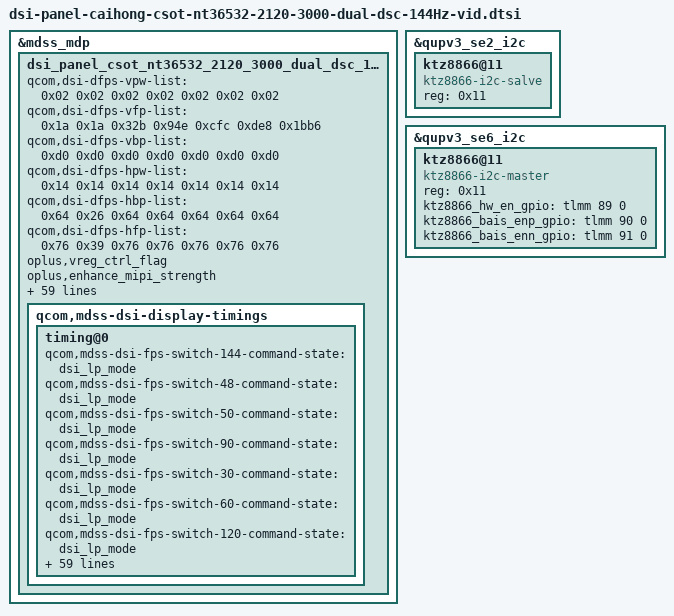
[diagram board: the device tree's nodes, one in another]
&mdss_mdp {
	dsi_panel_csot_nt36532_2120_3000_dual_dsc_144hz_vid: qcom,mdss_dsi_panel_csot_nt36532_2120_3000_dual_dsc_144hz_vid {
		qcom,dsi-dfps-vpw-list = <0x02 0x02 0x02 0x02 0x02 0x02 0x02>;
		qcom,dsi-dfps-vfp-list = <0x1a 0x1a 0x32b 0x94e 0xcfc 0xde8 0x1bb6>;
		qcom,dsi-dfps-vbp-list = <0xd0 0xd0 0xd0 0xd0 0xd0 0xd0 0xd0>;
		qcom,dsi-dfps-hpw-list = <0x14 0x14 0x14 0x14 0x14 0x14 0x14>;
		qcom,dsi-dfps-hbp-list = <0x64 0x26 0x64 0x64 0x64 0x64 0x64>;
		qcom,dsi-dfps-hfp-list = <0x76 0x39 0x76 0x76 0x76 0x76 0x76>;
		oplus,vreg_ctrl_flag;
		oplus,enhance_mipi_strength;
		oplus,dsi-cabc-enabled;
		qcom,mdss-dsi-panel-blackness-level = <0x7ff>;
		qcom,mdss-dsi-panel-average-brightness = <0x1e8480>;
		qcom,mdss-dsi-panel-peak-brightness = <0x5265c0>;
		qcom,mdss-dsi-panel-hdr-color-primaries = <0x3d13 0x4042 0x84d0 0x3e80 0x33c2 0x86c4 0x1d4c 0xbb8>;
		qcom,mdss-dsi-panel-hdr-enabled;
		qcom,mdss-pan-physical-height-dimension = <0xb1>;
		qcom,mdss-pan-physical-width-dimension = <0xfa>;
		qcom,mdss-dsi-reset-sequence = <0x01 0x0a 0x00 0x05 0x01 0x0a>;
		qcom,mdss-dsi-lp11-init;
		qcom,mdss-dsi-tx-eot-append;
		qcom,mdss-dsi-mdp-trigger = "none";
		qcom,mdss-dsi-dma-trigger = "trigger_sw";
		qcom,mdss-dsi-lane-3-state;
		qcom,mdss-dsi-lane-2-state;
		qcom,mdss-dsi-lane-1-state;
		qcom,mdss-dsi-lane-0-state;
		qcom,mdss-dsi-bllp-power-mode;
		qcom,mdss-dsi-bllp-eof-power-mode;
		qcom,bl-update-flag = "delay_until_first_frame";
		qcom,mdss-dsi-traffic-mode = "non_burst_sync_event";
		qcom,mdss-dsi-border-color = <0x00>;
		qcom,mdss-dsi-bpp = <0x18>;
		qcom,mdss-dsi-stream = <0x00>;
		qcom,mdss-dsi-virtual-channel-id = <0x00>;
		oplus,mdss-dsi-manufacture = "csot-novatek";
		oplus,mdss-dsi-vendor-name = "CSOT-NT36532";
		qcom,mdss-dsi-panel-type = "dsi_video_mode";
		qcom,mdss-dsi-panel-name = "Dual dsi csot nt36532 video mode panel with DSC";

		qcom,mdss-dsi-display-timings {
			timing@0 {
				qcom,mdss-dsi-fps-switch-144-command-state = "dsi_lp_mode";
				qcom,mdss-dsi-fps-switch-48-command-state = "dsi_lp_mode";
				qcom,mdss-dsi-fps-switch-50-command-state = "dsi_lp_mode";
				qcom,mdss-dsi-fps-switch-90-command-state = "dsi_lp_mode";
				qcom,mdss-dsi-fps-switch-30-command-state = "dsi_lp_mode";
				qcom,mdss-dsi-fps-switch-60-command-state = "dsi_lp_mode";
				qcom,mdss-dsi-fps-switch-120-command-state = "dsi_lp_mode";
				qcom,default-topology-index = <0x00>;
				qcom,display-topology = <0x04 0x04 0x02>;
				qcom,mdss-dsi-fps-switch-144-command = [39 00 00 40 00 00 02 b2 00 39 00 00 00 00 00 02 b3 00];
				qcom,mdss-dsi-fps-switch-48-command = [39 00 00 40 00 00 02 b2 00 39 00 00 00 00 00 02 b3 80];
				qcom,mdss-dsi-fps-switch-50-command = [39 00 00 40 00 00 02 b2 00 39 00 00 00 00 00 02 b3 80];
				qcom,mdss-dsi-fps-switch-90-command = [39 00 00 40 00 00 02 b2 00 39 00 00 00 00 00 02 b3 80];
				qcom,mdss-dsi-fps-switch-30-command = [39 00 00 40 00 00 02 b2 91 39 00 00 00 00 00 02 b3 40];
				qcom,mdss-dsi-fps-switch-60-command = [39 00 00 40 00 00 02 b2 91 39 00 00 00 00 00 02 b3 40];
				qcom,mdss-dsi-fps-switch-120-command = [39 00 00 40 00 00 02 b2 91 39 00 00 00 00 00 02 b3 40];
				qcom,mdss-dsc-block-prediction-enable;
				qcom,mdss-dsc-bit-per-pixel = <0x08>;
				qcom,mdss-dsc-bit-per-component = <0x08>;
				qcom,mdss-dsc-slice-per-pkt = <0x02>;
				qcom,mdss-dsc-slice-width = <0x2ee>;
				qcom,mdss-dsc-slice-height = <0x14>;
				qcom,mdss-dsc-encoders = <0x01>;
				qcom,mdss-dsc-version = <0x12>;
				qcom,compression-mode = "dsc";
				qcom,mdss-dsi-h-sync-pulse = <0x00>;
				qcom,mdss-dsi-cabc-off-command-state = "dsi_hs_mode";
				qcom,mdss-dsi-cabc-video-command-state = "dsi_hs_mode";
				qcom,mdss-dsi-cabc-still-image-command-state = "dsi_hs_mode";
				qcom,mdss-dsi-cabc-ui-command-state = "dsi_hs_mode";
				qcom,mdss-dsi-cabc-off-command = [39 00 00 40 00 00 02 b9 00 39 00 00 40 00 00 02 55 00 39 00 00 00 00 00 02 b9 02];
				qcom,mdss-dsi-cabc-video-command = [39 00 00 40 00 00 02 b9 00 39 00 00 40 00 00 02 55 03 39 00 00 00 00 00 02 b9 02];
				qcom,mdss-dsi-cabc-still-image-command = [39 00 00 40 00 00 02 b9 00 39 00 00 40 00 00 02 55 02 39 00 00 00 00 00 02 b9 02];
				qcom,mdss-dsi-cabc-ui-command = [39 00 00 40 00 00 02 b9 00 39 00 00 40 00 00 02 55 01 39 00 00 00 00 00 02 b9 02];
				qcom,mdss-dsi-off-command-state = "dsi_lp_mode";
				qcom,mdss-dsi-on-command-state = "dsi_lp_mode";
				qcom,mdss-dsi-off-command = [15 01 00 00 0a 00 02 28 00 15 01 00 00 41 00 02 10 00];
				qcom,mdss-dsi-on-command = [39 01 00 00 00 00 02 ff 22 39 01 00 00 00 00 02 fb 01 39 01 00 00 00 00 02 2d 01 39 01 00 00 00 00 02 ff 24 39 01 00 00 00 00 02 fb 01 39 01 00 00 00 00 07 bc 00 00 03 22 00 41 15 01 00 00 00 00 02 ff 23 15 01 00 00 00 00 02 fb 01 15 01 00 00 00 00 02 00 60 15 01 00 00 00 00 02 07 20 15 01 00 00 00 00 02 08 01 15 01 00 00 00 00 02 09 5a 15 01 00 00 00 00 02 10 0c 15 01 00 00 00 00 02 11 03 15 01 00 00 00 00 02 12 e1 15 01 00 00 00 00 02 15 a9 15 01 00 00 00 00 02 16 16 15 01 00 00 00 00 02 0a 8e 15 01 00 00 00 00 02 0b 8e 15 01 00 00 00 00 02 0c 8e 15 01 00 00 00 00 02 0d 00 15 01 00 00 00 00 02 19 00 15 01 00 00 00 00 02 1a 04 15 01 00 00 00 00 02 1b 08 15 01 00 00 00 00 02 1c 0c 15 01 00 00 00 00 02 1d 10 15 01 00 00 00 00 02 1e 14 15 01 00 00 00 00 02 1f 18 15 01 00 00 00 00 02 20 1c 15 01 00 00 00 00 02 21 20 15 01 00 00 00 00 02 22 24 15 01 00 00 00 00 02 23 28 15 01 00 00 00 00 02 24 2c 15 01 00 00 00 00 02 25 30 15 01 00 00 00 00 02 26 34 15 01 00 00 00 00 02 27 38 15 01 00 00 00 00 02 28 3c 15 01 00 00 00 00 02 2a 20 15 01 00 00 00 00 02 2b 20 15 01 00 00 00 00 02 30 ff 15 01 00 00 00 00 02 31 fd 15 01 00 00 00 00 02 32 fc 15 01 00 00 00 00 02 33 fa 15 01 00 00 00 00 02 34 f8 15 01 00 00 00 00 02 35 f6 15 01 00 00 00 00 02 36 f4 15 01 00 00 00 00 02 37 f2 15 01 00 00 00 00 02 38 f0 15 01 00 00 00 00 02 39 ee 15 01 00 00 00 00 02 3a ec 15 01 00 00 00 00 02 3b ea 15 01 00 00 00 00 02 3d e9 15 01 00 00 00 00 02 3f e8 15 01 00 00 00 00 02 40 e7 15 01 00 00 00 00 02 41 e6 15 01 00 00 00 00 02 45 ff 15 01 00 00 00 00 02 46 f9 15 01 00 00 00 00 02 47 f6 15 01 00 00 00 00 02 48 f2 15 01 00 00 00 00 02 49 f0 15 01 00 00 00 00 02 4a ec 15 01 00 00 00 00 02 4b e8 15 01 00 00 00 00 02 4c e4 15 01 00 00 00 00 02 4d e0 15 01 00 00 00 00 02 4e de 15 01 00 00 00 00 02 4f d9 15 01 00 00 00 00 02 50 d6 15 01 00 00 00 00 02 51 d4 15 01 00 00 00 00 02 52 c2 15 01 00 00 00 00 02 53 d0 15 01 00 00 00 00 02 54 cd 15 01 00 00 00 00 02 58 ff 15 01 00 00 00 00 02 59 f6 15 01 00 00 00 00 02 5a f0 15 01 00 00 00 00 02 5b eb 15 01 00 00 00 00 02 5c e8 15 01 00 00 00 00 02 5d e5 15 01 00 00 00 00 02 5e e3 15 01 00 00 00 00 02 5f e0 15 01 00 00 00 00 02 60 de 15 01 00 00 00 00 02 61 da 15 01 00 00 00 00 02 62 d7 15 01 00 00 00 00 02 63 d4 15 01 00 00 00 00 02 64 d2 15 01 00 00 00 00 02 65 d0 15 01 00 00 00 00 02 66 cc 15 01 00 00 00 00 02 67 c8 39 01 00 00 00 00 02 ff 27 39 01 00 00 00 00 02 fb 01 39 01 00 00 00 00 02 30 f0 39 01 00 00 00 00 03 31 2a 00 39 01 00 00 00 00 02 d0 31 39 01 00 00 00 00 02 d1 54 39 01 00 00 00 00 02 de 40 39 01 00 00 00 00 02 df 02 39 01 00 00 00 00 02 ff 2a 39 01 00 00 00 00 02 fb 01 39 01 00 00 00 00 02 c4 02 39 01 00 00 00 00 02 ff f0 39 01 00 00 00 00 02 fb 01 39 01 00 00 00 00 02 fa 05 39 01 00 00 00 00 02 76 16 39 01 00 00 00 00 02 ff 23 39 01 00 00 00 00 02 fb 01 39 01 00 00 00 00 03 ba aa 2a 39 01 00 00 00 00 03 bb a0 2a 39 01 00 00 00 00 02 ff 27 39 01 00 00 00 00 02 fb 01 39 01 00 00 00 00 02 01 8c 39 01 00 00 00 00 02 ff 10 39 01 00 00 00 00 02 fb 01 39 01 00 00 00 00 03 51 07 ff 39 01 00 00 00 00 02 53 2c 39 01 00 00 00 00 02 b9 00 39 01 00 00 00 00 02 55 01 39 01 00 00 00 00 02 b9 02 39 01 00 00 00 00 07 3b 03 d2 1a 04 04 00 39 01 00 00 00 00 02 90 03 39 01 00 00 00 00 11 91 89 a8 00 14 d2 00 00 00 02 1e 00 0a 05 7a 03 aa 39 01 00 00 00 00 03 92 10 f0 39 01 00 00 00 00 02 9d 01 39 01 00 00 00 00 02 b2 91 39 01 00 00 00 00 02 b3 40 15 01 00 00 78 00 02 11 00 15 01 00 00 0a 00 02 29 00];
				qcom,mdss-dsi-panel-clockrate = <0x4acbe680>;
				qcom,mdss-dsi-panel-framerate = <0x78>;
				qcom,mdss-dsi-v-pulse-width = <0x02>;
				qcom,mdss-dsi-v-front-porch = <0x1a>;
				qcom,mdss-dsi-v-back-porch = <0xd0>;
				qcom,mdss-dsi-h-sync-skew = <0x00>;
				qcom,mdss-dsi-h-pulse-width = <0x14>;
				qcom,mdss-dsi-h-back-porch = <0x64>;
				qcom,mdss-dsi-h-front-porch = <0x76>;
				qcom,mdss-dsi-panel-height = <0x848>;
				qcom,mdss-dsi-panel-width = <0x5dc>;
			};
		};
	};
};

&dsi_panel_csot_nt36532_2120_3000_dual_dsc_144hz_vid {
	qcom,panel-supply-entries = <&oplus_dsi_panel_custom_pwr_supply>;
	qcom,dsi-ctrl-num = <0 1>;
	qcom,dsi-phy-num = <0 1>;
	qcom,dsi-select-clocks = "pll_byte_clk0", "pll_dsi_clk0";
	qcom,mdss-dsi-bl-pmic-control-type = "bl_ctrl_external";
	qcom,mdss-dsi-bl-min-level = <2>;
	qcom,mdss-dsi-bl-max-level = <2047>;
	qcom,mdss-brightness-max-level = <2047>;
	qcom,mdss-dsi-bl-inverted-dbv;
	oplus,dsi-brightness-default-level = <717>;
	qcom,platform-reset-gpio = <&tlmm 133 0>;
	qcom,esd-check-enabled;
	qcom,mdss-dsi-panel-status-check-mode = "error_flag";
	qcom,error-flag-gpio = <&tlmm 86 0>;
	qcom,error-flag-gpio-slave = <&tlmm 43 0>;
	oplus,bl-use-ktz8866-ic-ctrl;
	oplus,dp-enabled;

	qcom,mdss-dsi-pan-enable-dynamic-fps;
	qcom,mdss-dsi-pan-fps-update = "dfps_immediate_porch_mode_vfp";
	qcom,dsi-supported-dfps-list = <120 60 30>;
};

&qupv3_se2_i2c {
	status = "ok";
	ktz8866@11 {
		compatible = "ktz8866-i2c-salve";
		reg = <0x11>;
	};
};

&qupv3_se6_i2c {
	status = "ok";
	ktz8866@11 {
		compatible = "ktz8866-i2c-master";
		reg = <0x11>;
		ktz8866_hw_en_gpio = <&tlmm 89 0>;
		ktz8866_bais_enp_gpio = <&tlmm 90 0>;
		ktz8866_bais_enn_gpio = <&tlmm 91 0>;
	};
};
